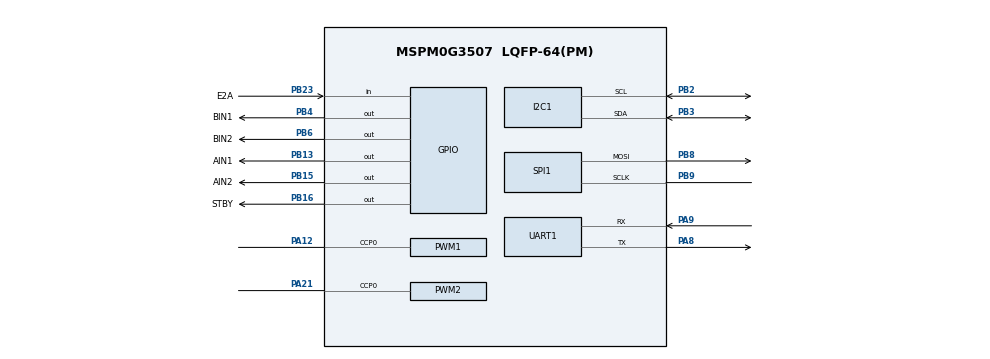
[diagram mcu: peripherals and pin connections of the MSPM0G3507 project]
/**
 * These arguments were used when this file was generated. They will be automatically applied on subsequent loads
 * via the GUI or CLI. Run CLI with '--help' for additional information on how to override these arguments.
 * @cliArgs --device "MSPM0G350X" --part "Default" --package "LQFP-64(PM)" --product "mspm0_sdk@2.05.01.00"
 * @v2CliArgs --device "MSPM0G3507" --package "LQFP-64(PM)" --product "mspm0_sdk@2.05.01.00"
 * @versions {"tool":"1.24.1+4189"}
 */

/**
 * Import the modules used in this configuration.
 */
const GPIO    = scripting.addModule("/ti/driverlib/GPIO", {}, false);
const GPIO1   = GPIO.addInstance();
const GPIO2   = GPIO.addInstance();
const GPIO3   = GPIO.addInstance();
const GPIO4   = GPIO.addInstance();
const GPIO5   = GPIO.addInstance();
const I2C     = scripting.addModule("/ti/driverlib/I2C", {}, false);
const I2C1    = I2C.addInstance();
const PWM     = scripting.addModule("/ti/driverlib/PWM", {}, false);
const PWM1    = PWM.addInstance();
const PWM2    = PWM.addInstance();
const SPI     = scripting.addModule("/ti/driverlib/SPI", {}, false);
const SPI1    = SPI.addInstance();
const SYSCTL  = scripting.addModule("/ti/driverlib/SYSCTL");
const SYSTICK = scripting.addModule("/ti/driverlib/SYSTICK");
const UART    = scripting.addModule("/ti/driverlib/UART", {}, false);
const UART1   = UART.addInstance();

/**
 * Write custom configuration values to the imported modules.
 */
const divider7       = system.clockTree["PLL_PDIV"];
divider7.divideValue = 2;

const divider9       = system.clockTree["UDIV"];
divider9.divideValue = 2;

const multiplier2         = system.clockTree["PLL_QDIV"];
multiplier2.multiplyValue = 5;

const mux8       = system.clockTree["HSCLKMUX"];
mux8.inputSelect = "HSCLKMUX_SYSPLL2X";

GPIO1.$name                          = "SPI_OLED_CTRL";
GPIO1.port                           = "PORTB";
GPIO1.associatedPins.create(3);
GPIO1.associatedPins[0].initialValue = "SET";
GPIO1.associatedPins[0].assignedPin  = "14";
GPIO1.associatedPins[0].$name        = "CS";
GPIO1.associatedPins[1].initialValue = "SET";
GPIO1.associatedPins[1].assignedPin  = "11";
GPIO1.associatedPins[1].$name        = "DC";
GPIO1.associatedPins[2].initialValue = "SET";
GPIO1.associatedPins[2].assignedPin  = "10";
GPIO1.associatedPins[2].$name        = "RES";

const Board = scripting.addModule("/ti/driverlib/Board", {}, false);

GPIO2.$name                              = "GPIO_GRAY";
GPIO2.associatedPins.create(8);
GPIO2.associatedPins[0].$name            = "PIN_0";
GPIO2.associatedPins[0].direction        = "INPUT";
GPIO2.associatedPins[0].assignedPort     = "PORTB";
GPIO2.associatedPins[0].assignedPin      = "19";
GPIO2.associatedPins[0].internalResistor = "PULL_UP";
GPIO2.associatedPins[1].$name            = "PIN_1";
GPIO2.associatedPins[1].direction        = "INPUT";
GPIO2.associatedPins[1].assignedPort     = "PORTB";
GPIO2.associatedPins[1].assignedPin      = "17";
GPIO2.associatedPins[1].internalResistor = "PULL_UP";
GPIO2.associatedPins[2].$name            = "PIN_2";
GPIO2.associatedPins[2].direction        = "INPUT";
GPIO2.associatedPins[2].assignedPort     = "PORTA";
GPIO2.associatedPins[2].assignedPin      = "16";
GPIO2.associatedPins[2].internalResistor = "PULL_UP";
GPIO2.associatedPins[3].$name            = "PIN_3";
GPIO2.associatedPins[3].direction        = "INPUT";
GPIO2.associatedPins[3].assignedPort     = "PORTA";
GPIO2.associatedPins[3].assignedPin      = "14";
GPIO2.associatedPins[3].internalResistor = "PULL_UP";
GPIO2.associatedPins[4].$name            = "PIN_4";
GPIO2.associatedPins[4].direction        = "INPUT";
GPIO2.associatedPins[4].assignedPort     = "PORTB";
GPIO2.associatedPins[4].assignedPin      = "20";
GPIO2.associatedPins[4].internalResistor = "PULL_UP";
GPIO2.associatedPins[5].$name            = "PIN_5";
GPIO2.associatedPins[5].direction        = "INPUT";
GPIO2.associatedPins[5].assignedPort     = "PORTB";
GPIO2.associatedPins[5].assignedPin      = "25";
GPIO2.associatedPins[5].internalResistor = "PULL_UP";
GPIO2.associatedPins[6].$name            = "PIN_6";
GPIO2.associatedPins[6].direction        = "INPUT";
GPIO2.associatedPins[6].assignedPort     = "PORTA";
GPIO2.associatedPins[6].assignedPin      = "25";
GPIO2.associatedPins[6].internalResistor = "PULL_UP";
GPIO2.associatedPins[7].$name            = "PIN_7";
GPIO2.associatedPins[7].direction        = "INPUT";
GPIO2.associatedPins[7].assignedPort     = "PORTA";
GPIO2.associatedPins[7].assignedPin      = "27";
GPIO2.associatedPins[7].internalResistor = "PULL_UP";

GPIO3.$name                          = "GPIO_MOTOR";
GPIO3.associatedPins.create(5);
GPIO3.associatedPins[0].$name        = "AIN1";
GPIO3.associatedPins[0].assignedPort = "PORTB";
GPIO3.associatedPins[0].pin.$assign  = "PB13";
GPIO3.associatedPins[1].$name        = "AIN2";
GPIO3.associatedPins[1].pin.$assign  = "PB15";
GPIO3.associatedPins[2].$name        = "STBY";
GPIO3.associatedPins[2].initialValue = "SET";
GPIO3.associatedPins[2].pin.$assign  = "PB16";
GPIO3.associatedPins[3].$name        = "BIN1";
GPIO3.associatedPins[3].assignedPort = "PORTB";
GPIO3.associatedPins[3].pin.$assign  = "PB4";
GPIO3.associatedPins[4].$name        = "BIN2";
GPIO3.associatedPins[4].pin.$assign  = "PB6";

GPIO4.$name                              = "GPIO_ENCODERA";
GPIO4.port                               = "PORTB";
GPIO4.associatedPins.create(2);
GPIO4.associatedPins[0].$name            = "E1A";
GPIO4.associatedPins[0].direction        = "INPUT";
GPIO4.associatedPins[0].internalResistor = "PULL_UP";
GPIO4.associatedPins[0].interruptEn      = true;
GPIO4.associatedPins[0].polarity         = "RISE_FALL";
GPIO4.associatedPins[0].assignedPin      = "0";
GPIO4.associatedPins[1].$name            = "E1B";
GPIO4.associatedPins[1].direction        = "INPUT";
GPIO4.associatedPins[1].internalResistor = "PULL_UP";
GPIO4.associatedPins[1].interruptEn      = true;
GPIO4.associatedPins[1].polarity         = "RISE_FALL";
GPIO4.associatedPins[1].assignedPin      = "5";

GPIO5.$name                              = "GPIO_ENCODERB";
GPIO5.port                               = "PORTB";
GPIO5.associatedPins.create(2);
GPIO5.associatedPins[0].$name            = "E2A";
GPIO5.associatedPins[0].direction        = "INPUT";
GPIO5.associatedPins[0].interruptEn      = true;
GPIO5.associatedPins[0].polarity         = "RISE_FALL";
GPIO5.associatedPins[0].assignedPin      = "23";
GPIO5.associatedPins[0].pin.$assign      = "PB23";
GPIO5.associatedPins[1].$name            = "E2B";
GPIO5.associatedPins[1].direction        = "INPUT";
GPIO5.associatedPins[1].internalResistor = "PULL_UP";
GPIO5.associatedPins[1].interruptEn      = true;
GPIO5.associatedPins[1].polarity         = "RISE_FALL";
GPIO5.associatedPins[1].assignedPin      = "18";

I2C1.basicEnableController             = true;
I2C1.basicControllerStandardBusSpeed   = "Fast";
I2C1.$name                             = "I2C";
I2C1.peripheral.$assign                = "I2C1";
I2C1.peripheral.sdaPin.$assign         = "PB3";
I2C1.peripheral.sclPin.$assign         = "PB2";
I2C1.sdaPinConfig.$name                = "ti_driverlib_gpio_GPIOPinGeneric0";
I2C1.sdaPinConfig.hideOutputInversion  = scripting.forceWrite(false);
I2C1.sdaPinConfig.onlyInternalResistor = scripting.forceWrite(false);
I2C1.sdaPinConfig.passedPeripheralType = scripting.forceWrite("Digital");
I2C1.sdaPinConfig.enableConfig         = true;
I2C1.sclPinConfig.$name                = "ti_driverlib_gpio_GPIOPinGeneric1";
I2C1.sclPinConfig.hideOutputInversion  = scripting.forceWrite(false);
I2C1.sclPinConfig.onlyInternalResistor = scripting.forceWrite(false);
I2C1.sclPinConfig.passedPeripheralType = scripting.forceWrite("Digital");
I2C1.sclPinConfig.enableConfig         = true;

PWM1.$name                              = "PWMA";
PWM1.timerStartTimer                    = true;
PWM1.ccIndex                            = [0];
PWM1.timerCount                         = 4000;
PWM1.pwmMode                            = "EDGE_ALIGN_UP";
PWM1.PWM_CHANNEL_0.$name                = "ti_driverlib_pwm_PWMTimerCC0";
PWM1.ccp0PinConfig.$name                = "ti_driverlib_gpio_GPIOPinGeneric2";
PWM1.ccp0PinConfig.direction            = scripting.forceWrite("OUTPUT");
PWM1.ccp0PinConfig.hideOutputInversion  = scripting.forceWrite(false);
PWM1.ccp0PinConfig.onlyInternalResistor = scripting.forceWrite(false);
PWM1.ccp0PinConfig.passedPeripheralType = scripting.forceWrite("Digital");
PWM1.peripheral.$assign                 = "TIMG0";
PWM1.peripheral.ccp0Pin.$assign         = "PA12";

PWM2.$name                              = "PWMB";
PWM2.timerStartTimer                    = true;
PWM2.timerCount                         = 4000;
PWM2.clockPrescale                      = 2;
PWM2.pwmMode                            = "EDGE_ALIGN_UP";
PWM2.ccIndex                            = [0];
PWM2.PWM_CHANNEL_0.$name                = "ti_driverlib_pwm_PWMTimerCC1";
PWM2.ccp0PinConfig.direction            = scripting.forceWrite("OUTPUT");
PWM2.ccp0PinConfig.hideOutputInversion  = scripting.forceWrite(false);
PWM2.ccp0PinConfig.onlyInternalResistor = scripting.forceWrite(false);
PWM2.ccp0PinConfig.passedPeripheralType = scripting.forceWrite("Digital");
PWM2.ccp0PinConfig.$name                = "ti_driverlib_gpio_GPIOPinGeneric5";
PWM2.peripheral.$assign                 = "TIMG6";
PWM2.peripheral.ccp0Pin.$assign         = "PA21";

SPI1.$name                              = "SPI_OLED";
SPI1.targetBitRate                      = 20000000;
SPI1.frameFormat                        = "MOTO3";
SPI1.sclkPinConfig.direction            = scripting.forceWrite("OUTPUT");
SPI1.sclkPinConfig.onlyInternalResistor = scripting.forceWrite(false);
SPI1.sclkPinConfig.passedPeripheralType = scripting.forceWrite("Digital");
SPI1.sclkPinConfig.$name                = "ti_driverlib_gpio_GPIOPinGeneric3";
SPI1.mosiPinConfig.direction            = scripting.forceWrite("OUTPUT");
SPI1.mosiPinConfig.hideOutputInversion  = scripting.forceWrite(false);
SPI1.mosiPinConfig.onlyInternalResistor = scripting.forceWrite(false);
SPI1.mosiPinConfig.passedPeripheralType = scripting.forceWrite("Digital");
SPI1.mosiPinConfig.$name                = "ti_driverlib_gpio_GPIOPinGeneric4";
SPI1.misoPinConfig.onlyInternalResistor = scripting.forceWrite(false);
SPI1.misoPinConfig.passedPeripheralType = scripting.forceWrite("Digital");
SPI1.misoPinConfig.$name                = "ti_driverlib_gpio_GPIOPinGeneric12";
SPI1.peripheral.$assign                 = "SPI1";
SPI1.peripheral.sclkPin.$assign         = "PB9";
SPI1.peripheral.mosiPin.$assign         = "PB8";

SYSCTL.forceDefaultClkConfig = true;
SYSCTL.clockTreeEn           = true;
scripting.suppress("For best practices when the CPUCLK is running at 32MHz and above, clear the flash status bit using DL_FlashCTL_executeClearStatus\\(\\) before executing any flash operation\\. Otherwise there may be false positives\\.", SYSCTL);

SYSTICK.periodEnable  = true;
SYSTICK.systickEnable = true;
SYSTICK.period        = 16777216;

UART1.$name                            = "IMU601";
UART1.targetBaudRate                   = 115200;
UART1.enabledInterrupts                = ["RX"];
UART1.peripheral.$assign               = "UART1";
UART1.peripheral.rxPin.$assign         = "PA9";
UART1.peripheral.txPin.$assign         = "PA8";
UART1.txPinConfig.direction            = scripting.forceWrite("OUTPUT");
UART1.txPinConfig.hideOutputInversion  = scripting.forceWrite(false);
UART1.txPinConfig.onlyInternalResistor = scripting.forceWrite(false);
UART1.txPinConfig.passedPeripheralType = scripting.forceWrite("Digital");
UART1.txPinConfig.$name                = "ti_driverlib_gpio_GPIOPinGeneric7";
UART1.rxPinConfig.hideOutputInversion  = scripting.forceWrite(false);
UART1.rxPinConfig.onlyInternalResistor = scripting.forceWrite(false);
UART1.rxPinConfig.passedPeripheralType = scripting.forceWrite("Digital");
UART1.rxPinConfig.$name                = "ti_driverlib_gpio_GPIOPinGeneric9";

/**
 * Pinmux solution for unlocked pins/peripherals. This ensures that minor changes to the automatic solver in a future
 * version of the tool will not impact the pinmux you originally saw.  These lines can be completely deleted in order to
 * re-solve from scratch.
 */
GPIO1.associatedPins[0].pin.$suggestSolution = "PB14";
GPIO1.associatedPins[1].pin.$suggestSolution = "PB11";
GPIO1.associatedPins[2].pin.$suggestSolution = "PB10";
Board.peripheral.$suggestSolution            = "DEBUGSS";
Board.peripheral.swclkPin.$suggestSolution   = "PA20";
Board.peripheral.swdioPin.$suggestSolution   = "PA19";
GPIO2.associatedPins[0].pin.$suggestSolution = "PB19";
GPIO2.associatedPins[1].pin.$suggestSolution = "PB17";
GPIO2.associatedPins[2].pin.$suggestSolution = "PA16";
GPIO2.associatedPins[3].pin.$suggestSolution = "PA14";
GPIO2.associatedPins[4].pin.$suggestSolution = "PB20";
GPIO2.associatedPins[5].pin.$suggestSolution = "PB25";
GPIO2.associatedPins[6].pin.$suggestSolution = "PA25";
GPIO2.associatedPins[7].pin.$suggestSolution = "PA27";
GPIO4.associatedPins[0].pin.$suggestSolution = "PB0";
GPIO4.associatedPins[1].pin.$suggestSolution = "PB5";
GPIO5.associatedPins[1].pin.$suggestSolution = "PB18";
SPI1.peripheral.misoPin.$suggestSolution     = "PB21";
